CM_ "IMPORT _bosch_2018.dbc";

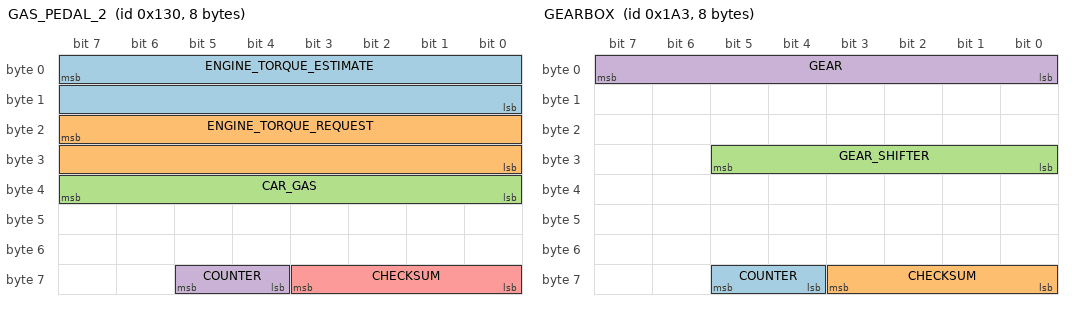
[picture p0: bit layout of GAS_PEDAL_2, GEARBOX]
BO_ 304 GAS_PEDAL_2: 8 PCM
 SG_ ENGINE_TORQUE_ESTIMATE : 7|16@0- (1,0) [-1000|1000] "Nm" EON
 SG_ ENGINE_TORQUE_REQUEST : 23|16@0- (1,0) [-1000|1000] "Nm" EON
 SG_ CAR_GAS : 39|8@0+ (1,0) [0|255] "" EON
 SG_ COUNTER : 61|2@0+ (1,0) [0|3] "" EON
 SG_ CHECKSUM : 59|4@0+ (1,0) [0|15] "" EON

BO_ 419 GEARBOX: 8 PCM
 SG_ COUNTER : 61|2@0+ (1,0) [0|3] "" EON
 SG_ CHECKSUM : 59|4@0+ (1,0) [0|3] "" EON
 SG_ GEAR_SHIFTER : 29|6@0+ (1,0) [0|63] "" EON
 SG_ GEAR : 7|8@0+ (1,0) [0|255] "" EON

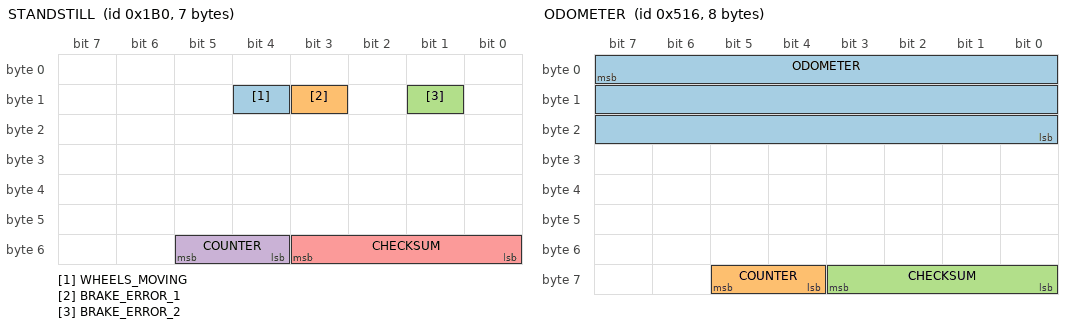
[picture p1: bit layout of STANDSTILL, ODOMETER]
BO_ 432 STANDSTILL: 7 VSA
 SG_ WHEELS_MOVING : 12|1@0+ (1,0) [0|1] "" EON
 SG_ BRAKE_ERROR_1 : 11|1@0+ (1,0) [0|1] "" EON
 SG_ BRAKE_ERROR_2 : 9|1@0+ (1,0) [0|1] "" EON
 SG_ COUNTER : 53|2@0+ (1,0) [0|3] "" EON
 SG_ CHECKSUM : 51|4@0+ (1,0) [0|15] "" EON

BO_ 1302 ODOMETER: 8 XXX
 SG_ ODOMETER : 7|24@0+ (1,0) [0|16777215] "km" EON
 SG_ COUNTER : 61|2@0+ (1,0) [0|3] "" EON
 SG_ CHECKSUM : 59|4@0+ (1,0) [0|3] "" EON

CM_ SG_ 450 EPB_STATE "3: On, 2: Disengaging, 1: Engaging, 0: Off";
CM_ SG_ 479 CONTROL_ON "Set to 5 when car is being controlled";
CM_ SG_ 479 RELATED_TO_GAS "bits 7, 3, and 1 set to 1 when gas not applied";
CM_ SG_ 479 GAS_BRAKE "Signed value, negative when braking and positive when applying gas";

VAL_ 419 GEAR_SHIFTER  32 "D" 8 "R" 4 "P" ;
VAL_ 545 ECON_ON_2 0 "off" 3 "on" ;
VAL_ 662 CRUISE_BUTTONS 7 "tbd" 6 "tbd" 5 "tbd" 4 "accel_res" 3 "decel_set" 2 "cancel" 1 "main" 0 "none" ;
VAL_ 662 CRUISE_SETTING 3 "distance_adj" 2 "tbd" 1 "lkas_button" 0 "none" ;
VAL_ 806 CMBS_BUTTON 3 "pressed" 0 "released" ;
VAL_ 891 WIPERS 4 "High" 2 "Low" 0 "Off" ;
VAL_ 829 BEEP 3 "single_beep" 2 "triple_beep" 1 "repeated_beep" 0 "no_beep" ;
